# psoc6a2m register map
Vendor: Cypress Semiconductor; Series: psoc6a2m; File version: 1.0
CPU: CM4 r0p1, little endian, MPU, FPU, VTOR, 3 interrupt priority bits
Registers are 32-bit, read-write, reset 0x0 unless marked. A register's access mark holds for its fields unless they carry their own. Offsets are from the block's base; [hi:lo] are bit positions; lines under a group give offsets from that group.

## SDHC0 (part 4 of 4) — SD/eMMC Host Controller
Base 0x40460000
Same registers: SDHC1 0x40470000
0x1000 CORE group — MMIO for Synopsys Mobile Storage Host Controller IP
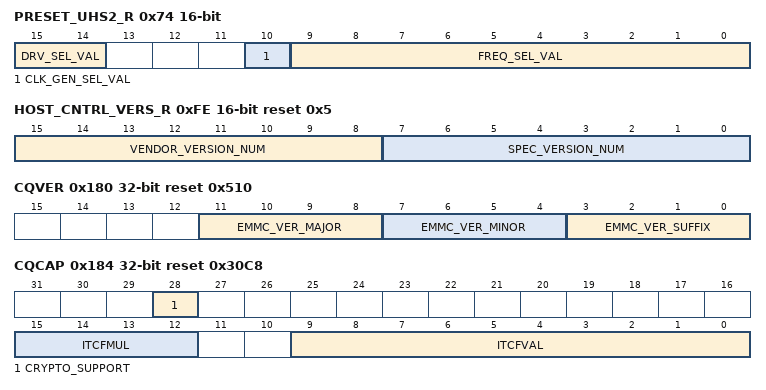
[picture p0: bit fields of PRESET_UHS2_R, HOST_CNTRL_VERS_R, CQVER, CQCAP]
  0x74 PRESET_UHS2_R 16-bit ro — Preset Value for UHS-II
    [15:14] DRV_SEL_VAL — Driver Strength Select Value These bits indicate the Driver strength value supported by 1.8V signaling bus speed modes in the SD mode. This field is meaningless for UHS-II mode. In eMMC mode, these bits can be used for selecting the Drive strength value for HS400 mode. Values: - 0x0 (TYPEB): Driver Type B is selected - 0x1 (TYPEA): Driver Type A is selected - 0x2 (TYPEC): Driver Type C is selected - 0x3 (TYPED): Driver Type D is selected
    [10] CLK_GEN_SEL_VAL — Clock Generator Select Value This bit is effective when the Host Controller supports a programmable clock generator. Values: - 0x0 (FALSE): Host Controller Ver2.0 Compatible Clock Generator - 0x1 (PROG): Programmable Clock Generator
    [9:0] FREQ_SEL_VAL — SDCLK/RCLK Frequency Select Value These bits specify the 10-bit preset value that must be set in the SDCLK/RCLK Frequency Select field of the Clock Control register, as described by a Host System.
  0x78 ADMA_ID_LOW_R — ADMA3 Integrated Descriptor Address Register - Low
    [31:0] ADMA_ID_LOW — ADMA Integrated Descriptor Address These bits indicate the lower 32-bit of the ADMA Integrated Descriptor address. The start address of Integrated Descriptor is set to these register bits. The ADMA3 fetches one Descriptor Address and increments these bits to indicate the next Descriptor address.
  0xE6 P_EMBEDDED_CNTRL 16-bit ro reset 0xF6C — Pointer for Embedded Control
    [11:0] REG_OFFSET_ADDR — Offset Address of Embedded Control register.
  0xE8 P_VENDOR_SPECIFIC_AREA 16-bit ro reset 0x500 — Pointer for Vendor Specific Area 1
    [11:0] REG_OFFSET_ADDR — Base offset Address for Vendor-Specific registers.
  0xEA P_VENDOR2_SPECIFIC_AREA 16-bit ro reset 0x180 — Pointer for Vendor Specific Area 2
    [15:0] V2SA_REG_OFFSET_ADDR — Base offset Address for Command Queuing registers.
  0xFC SLOT_INTR_STATUS_R 16-bit ro — Slot Interrupt Status Register
    [7:0] INTR_SLOT — Interrupt signal for each Slot These status bits indicate the logical OR of Interrupt signal and Wakeup signal for each slot. A maximum of 8 slots can be defined. If one interrupt signal is associated with multiple slots, the Host Driver can identify the interrupt that is generated by reading these bits. By a power on reset or by setting Software Reset For All bit, the interrupt signals are de-asserted and this status reads 00h. - Bit 00: Slot 1 - Bit 01: Slot 2 - Bit 02: Slot 3 - .......... - .......... - Bit 07: Slot 8 Note: MSHC Host Controller support single card slot. This register shall always return 0.
  0xFE HOST_CNTRL_VERS_R 16-bit ro reset 0x5 — Host Controller Version
    [15:8] VENDOR_VERSION_NUM, [7:0] SPEC_VERSION_NUM
  0x180 CQVER ro reset 0x510 — Command Queuing Version register
    [11:8] EMMC_VER_MAJOR — This bit indicates the eMMC major version (1st digit left of decimal point) in BCD format.
    [7:4] EMMC_VER_MINOR — This bit indicates the eMMC minor version (1st digit right of decimal point) in BCD format.
    [3:0] EMMC_VER_SUFFIX — This bit indicates the eMMC version suffix (2nd digit right of decimal point) in BCD format.
  0x184 CQCAP ro reset 0x30C8 — Command Queuing Capabilities register
    [28] CRYPTO_SUPPORT — Crypto Support This bit indicates whether the Host Controller supports cryptographic operations. Values: - 0x0 (FALSE): Crypto not Supported - 0x1 (TRUE): Crypto Supported
    [15:12] ITCFMUL
    [9:0] ITCFVAL — Internal Timer Clock Frequency Value (ITCFVAL) This field scales the frequency of the timer clock provided by ITCFMUL. The Final clock frequency of actual timer clock is calculated as ITCFVAL* ITCFMUL.
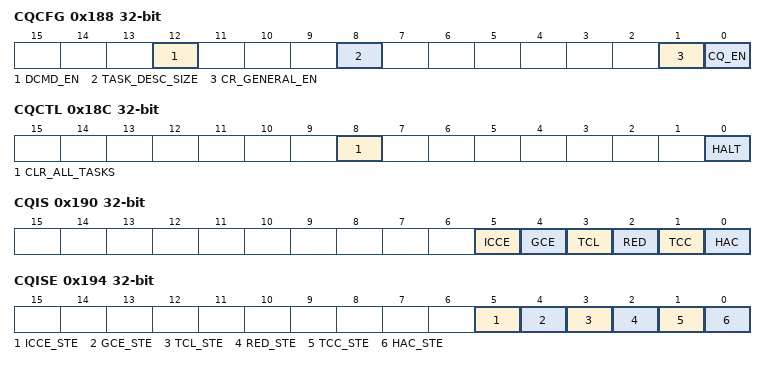
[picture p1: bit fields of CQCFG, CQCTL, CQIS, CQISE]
  0x188 CQCFG — Command Queuing Configuration register
    [12] DCMD_EN — This bit indicates to the hardware whether the Task Descriptor in slot #31 of the TDL is a data transfer descriptor or a direct-command descriptor. CQE uses this bit when a task is issued in slot #31, to determine how to decode the Task Descriptor. Values: - 0x1 (SLOT31_DCMD_ENABLE): Task descriptor in slot #31 is a DCMD Task Descriptor - 0x0 (SLOT31_DCMD_DISABLE): Task descriptor in slot #31 is a data Transfer Task Descriptor
    [8] TASK_DESC_SIZE — Bit Value Description This bit indicates the size of task descriptor used in host memory. This bit can only be configured when Command Queuing Enable bit is 0 (command queuing is disabled). Values: - 0x1 (TASK_DESC_128b): Task descriptor size is 128 bits - 0x0 (TASK_DESC_64b): Task descriptor size is 64 bits
    [1] CR_GENERAL_EN
    [0] CQ_EN — Enable command queuing engine (CQE). When CQE is disable, the software controls the eMMC bus using the registers between the addresses 0x000 to 0x1FF. Before the software writes to this bit, the software verifies that the eMMC host controller is in idle state and there are no ongoing commands or data transfers. When software wants to exit command queuing mode, it clears all previous tasks (if any) before setting this bit to 0. Values: - 0x1 (CQE_ENABLE): Enable command queuing - 0x0 (CQE_DISABLE): Disable command queuing
  0x18C CQCTL — Command Queuing Control register
    [8] CLR_ALL_TASKS — Clear all tasks This bit can only be written when the controller is halted. This bit does not clear tasks in the device. The software has to use the CMDQ_TASK_MGMT command to clear device's queue. Values: - 0x1 (CLEAR_ALL_TASKS): Clears all the tasks in the controller - 0x0 (NO_EFFECT): Programming 0 has no effect
    [0] HALT — Halt request and resume Values: - 0x1 (HALT_CQE): Software writes 1 to this bit when it wants to acquire software control over the eMMC bus and to disable CQE from issuing command on the bus. For example, issuing a Discard Task command (CMDQ_TASK_MGMT). When the software writes 1, CQE completes the ongoing task (if any in progress). After the task is completed and the CQE is in idle state, CQE does not issue new commands and indicates to the software by setting this bit to 1. The software can poll on this bit until it is set to 1 and only then send commands on the eMMC bus. - 0x0 (RESUME_CQE): Software writes 0 to this bit to exit from the halt state and resume CQE activity.
  0x190 CQIS — Command Queuing Interrupt Status register
    [5] ICCE
    [4] GCE
    [3] TCL — Task cleared interrupt This status bit is asserted (if CQISE.TCL_STE=1) when a task clear operation is completed by CQE. The completed task clear operation is either an individual task clear (by writing CQTCLR) or clearing of all tasks (by writing CQCTL). A value of 1 clears this status bit. Values: - 0x1 (SET): TCL Interrupt is set - 0x0 (NOTSET): TCL Interrupt is not set
    [2] RED — Response error detected interrupt This status bit is asserted (if CQISE.RED_STE=1) when a response is received with an error bit set in the device status field. Configure the CQRMEM register to identify device status bit fields that may trigger an interrupt and that are masked. A value of 1 clears this status bit. Values: - 0x1 (SET): RED Interrupt is set - 0x0 (NOTSET): RED Interrupt is not set
    [1] TCC — Task complete interrupt This status bit is asserted (if CQISE.TCC_STE=1) when at least one of the following conditions are met: - A task is completed and the INT bit is set in its Task Descriptor - Interrupt caused by Interrupt Coalescing logic due to timeout - Interrupt Coalescing logic reached the configured threshold A value of 1 clears this status bit Values: - 0x1 (SET): TCC Interrupt is set - 0x0 (NOTSET): TCC Interrupt is not set
    [0] HAC — Halt complete interrupt This status bit is asserted (only if CQISE.HAC_STE=1) when halt bit in the CQCTL register transitions from 0 to 1 indicating that the host controller has completed its current ongoing task and has entered halt state. A value of 1 clears this status bit. Values: - 0x1 (SET): HAC Interrupt is set - 0x0 (NOTSET): HAC Interrupt is not set
  0x194 CQISE — Command Queuing Interrupt Status Enable register
    [5] ICCE_STE — Invalid Crypto Configuration Error interrupt status enable Values: - 0x1 (INT_STS_ENABLE): CQIS.ICCE is set when its interrupt condition is active - 0x0 (INT_STS_DISABLE): CQIS.ICCE is disabled
    [4] GCE_STE — General Crypto Error interrupt status enable Values: - 0x1 (INT_STS_ENABLE): CQIS.GCE is set when its interrupt condition is active - 0x0 (INT_STS_DISABLE): CQIS.GCE is disabled
    [3] TCL_STE — Task cleared interrupt status enable Values: - 0x1 (INT_STS_ENABLE): CQIS.TCL is set when its interrupt condition is active - 0x0 (INT_STS_DISABLE): CQIS.TCL is disabled
    [2] RED_STE — Response error detected interrupt status enable Values: - 0x1 (INT_STS_ENABLE): CQIS.RED is set when its interrupt condition is active - 0x0 (INT_STS_DISABLE): CQIS.RED is disabled
    [1] TCC_STE — Task complete interrupt status enable Values: - 0x1 (INT_STS_ENABLE): CQIS.TCC is set when its interrupt condition is active - 0x0 (INT_STS_DISABLE): CQIS.TCC is disabled
    [0] HAC_STE — Halt complete interrupt status enable Values: - 0x1 (INT_STS_ENABLE): CQIS.HAC is set when its interrupt condition is active - 0x0 (INT_STS_DISABLE): CQIS.HAC is disabled
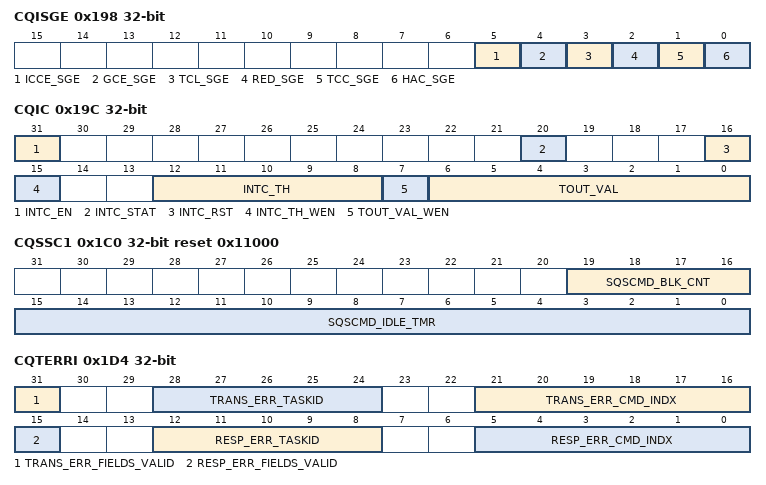
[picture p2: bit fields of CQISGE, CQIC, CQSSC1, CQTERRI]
  0x198 CQISGE — Command Queuing Interrupt signal enable register
    [5] ICCE_SGE — Invalid Crypto Configuration Error interrupt signal enable Values: - 0x1 (INT_SIG_ENABLE): CQIS.ICCE interrupt signal generation is active - 0x0 (INT_SIG_DISABLE): CQIS.ICCE interrupt signal generation is disabled
    [4] GCE_SGE — General Crypto Error interrupt signal enable Values: - 0x1 (INT_SIG_ENABLE): CQIS.GCE interrupt signal generation is active - 0x0 (INT_SIG_DISABLE): CQIS.GCE interrupt signal generation is disabled
    [3] TCL_SGE — Task cleared interrupt signal enable Values: - 0x1 (INT_SIG_ENABLE): CQIS.TCL interrupt signal generation is active - 0x0 (INT_SIG_DISABLE): CQIS.TCL interrupt signal generation is disabled
    [2] RED_SGE — Response error detected interrupt signal enable Values: - 0x1 (INT_SIG_ENABLE): CQIS.RED interrupt signal generation is active - 0x0 (INT_SIG_DISABLE): CQIS.RED interrupt signal generation is disabled
    [1] TCC_SGE — Task complete interrupt signal enable Values: - 0x1 (INT_SIG_ENABLE): CQIS.TCC interrupt signal generation is active - 0x0 (INT_SIG_DISABLE): CQIS.TCC interrupt signal generation is disabled
    [0] HAC_SGE — Halt complete interrupt signal enable Values: - 0x1 (INT_SIG_ENABLE): CQIS.HAC interrupt signal generation is active - 0x0 (INT_SIG_DISABLE): CQIS.HAC interrupt signal generation is disabled
  0x19C CQIC — Command Queuing Interrupt Coalescing register
    [31] INTC_EN — Interrupt Coalescing Enable Bit Values: - 0x1 (ENABLE_INT_COALESCING): Interrupt coalescing mechanism is active. Interrupts are counted and timed, and coalesced interrupts are generated - 0x0 (DISABLE_INT_COALESCING): Interrupt coalescing mechanism is disabled (Default).
    [20] INTC_STAT ro — Interrupt Coalescing Status Bit This bit indicates to the software whether any tasks (with INT=0) have completed and counted towards interrupt coalescing (that is, this is set if and only if INTC counter > 0). Values: - 0x1 (INTC_ATLEAST1_COMP): At least one INT0 task completion has been counted (INTC counter > 0) - 0x0 (INTC_NO_TASK_COMP): INT0 Task completions have not occurred since last counter reset (INTC counter == 0)
    [16] INTC_RST wo — Counter and Timer Reset When host driver writes 1, the interrupt coalescing timer and counter are reset. Values: - 0x1 (ASSERT_INTC_RESET): Interrupt coalescing timer and counter are reset - 0x0 (NO_EFFECT): No Effect
    [15] INTC_TH_WEN wo — Interrupt Coalescing Counter Threshold Write Enable When software writes 1 to this bit, the value INTC_TH is updated with the contents written on the same cycle. Values: - 0x1 (WEN_SET): Sets INTC_TH_WEN - 0x0 (WEN_CLR): Clears INTC_TH_WEN
    [12:8] INTC_TH wo — Interrupt Coalescing Counter Threshold filed Software uses this field to configure the number of task completions (only tasks with INT=0 in the Task Descriptor), which are required in order to generate an interrupt. Counter Operation: As data transfer tasks with INT=0 complete, they are counted by CQE. The counter is reset by software during the interrupt service routine. The counter stops counting when it reaches the value configured in INTC_TH, and generates interrupt. - 0x0: Interrupt coalescing feature disabled - 0x1: Interrupt coalescing interrupt generated after 1 task when INT=0 completes - 0x2: Interrupt coalescing interrupt generated after 2 tasks when INT=0 completes - ........ - 0x1f: Interrupt coalescing interrupt generated after 31 tasks when INT=0 completes To write to this field, the INTC_TH_WEN bit must be set during the same write operation.
    [7] TOUT_VAL_WEN wo — When software writes 1 to this bit, the value TOUT_VAL is updated with the contents written on the same cycle. Values: - 0x1 (WEN_SET): Sets TOUT_VAL_WEN - 0x0 (WEN_CLR): clears TOUT_VAL_WEN
    [6:0] TOUT_VAL — Interrupt Coalescing Timeout Value Software uses this field to configure the maximum time allowed between the completion of a task on the bus and the generation of an interrupt. Timer Operation: The timer is reset by software during the interrupt service routine. It starts running when the first data transfer task with INT=0 is completed, after the timer was reset. When the timer reaches the value configured in ICTOVAL field, it generates an interrupt and stops. The timer's unit is equal to 1024 clock periods of the clock whose frequency is specified in the Internal Timer Clock Frequency field CQCAP register. - 0x0: Timer is disabled. Timeout-based interrupt is not generated - 0x1: Timeout on 01x1024 cycles of timer clock frequency - 0x2: Timeout on 02x1024 cycles of timer clock frequency - ........ - 0x7f: Timeout on 127x1024 cycles of timer clock frequency In order to write to this field, the TOUT_VAL_WEN bit must be set at the same write operation.
  0x1A0 CQTDLBA — Command Queuing Task Descriptor List Base Address register
    [31:0] TDLBA — This register stores the LSB bits (31:0) of the byte address of the head of the Task Descriptor List in system memory. The size of the task descriptor list is 32 * (Task Descriptor size + Transfer Descriptor size) as configured by the host driver. This address is set on 1 KB boundary. The lower 10 bits of this register are set to 0 by the software and are ignored by CQE.
  0x1A8 CQTDBR — Command Queuing DoorBell register
    [31:0] DBR — The software configures TDLBA and TDLBAU, and enable CQE in CQCFG before using this register. Writing 1 to bit n of this register triggers CQE to start processing the task encoded in slot n of the TDL. Writing 0 by the software does not have any impact on the hardware, and does not change the value of the register bit. CQE always processes tasks according to the order submitted to the list by CQTDBR write transactions. CQE processes Data Transfer tasks by reading the Task Descriptor and sending QUEUED_TASK_PARAMS (CMD44) and QUEUED_TASK_ADDRESS (CMD45) commands to the device. CQE processes DCMD tasks (in slot #31, when enabled) by reading the Task Descriptor, and generating the command encoded by its index and argument. The corresponding bit is cleared to 0 by CQE in one of the following events: - A task execution is completed (with success or error). - The task is cleared using CQTCLR register. - All tasks are cleared using CQCTL register. - CQE is disabled using CQCFG register. Software may initiate multiple tasks at the same time (batch submission) by writing 1 to multiple bits of this register in the same transaction. In the case of batch submission, CQE processes the tasks in order of the task index, starting with the lowest index. If one or more tasks in the batch are marked with QBR, the ordering of execution is based on said processing order.
  0x1AC CQTCN — Command Queuing TaskClear Notification register
    [31:0] TCN — Task Completion Notification Each of the 32 bits are bit mapped to the 32 tasks. - Bit-N(1): Task-N has completed execution (with success or errors) - Bit-N(0): Task-N has not completed, could be pending or not submitted. On task completion, software may read this register to know tasks that have completed. After reading this register, software may clear the relevant bit fields by writing 1 to the corresponding bits.
  0x1B0 CQDQS ro — Device queue status register
    [31:0] DQS — Device Queue Status Each of the 32 bits are bit mapped to the 32 tasks. - Bit-N(1): Device has marked task N as ready for execution - Bit-N(0): Task-N is not ready for execution. This task could be pending in device or not submitted. Host controller updates this register with response of the Device Queue Status command.
  0x1B4 CQDPT ro — Device pending tasks register
    [31:0] DPT — Device-Pending Tasks Each of the 32 bits are bit mapped to the 32 tasks. - Bit-N(1): Task-N has been successfully queued into the device and is awaiting execution - Bit-N(0): Task-N is not yet queued. Bit n of this register is set if and only if QUEUED_TASK_PARAMS (CMD44) and QUEUED_TASK_ADDRESS (CMD45) were sent for this specific task and if this task has not been executed. The controller sets this bit after receiving a successful response for CMD45. CQE clears this bit after the task has completed execution. Software reads this register in the task-discard procedure to determine if the task is queued in the device.
  0x1B8 CQTCLR — Command Queuing DoorBell register
    [31:0] TCLR — Writing 1 to bit n of this register orders CQE to clear a task that the software has previously issued. This bit can only be written when CQE is in Halt state as indicated in CQCFG register Halt bit. When software writes 1 to a bit in this register, CQE updates the value to 1, and starts clearing the data structures related to the task. CQE clears the bit fields (sets a value of 0) in CQTCLR and in CQTDBR once the clear operation is complete. Software must poll on the CQTCLR until it is cleared to verify that a clear operation was done.
  0x1C0 CQSSC1 reset 0x11000 — CQ Send Status Configuration 1 register
    [19:16] SQSCMD_BLK_CNT — This field indicates when SQS CMD is sent while data transfer is in progress. A value of 'n' indicates that CQE sends status command on the CMD line, during the transfer of data block BLOCK_CNTn, on the data lines, where BLOCK_CNT is the number of blocks in the current transaction. - 0x0: SEND_QUEUE_STATUS (CMD13) command is not sent during the transaction. Instead, it is sent only when the data lines are idle. - 0x1: SEND_QUEUE_STATUS command is to be sent during the last block of the transaction. - 0x2: SEND_QUEUE_STATUS command when last 2 blocks are pending. - 0x3: SEND_QUEUE_STATUS command when last 3 blocks are pending. - ........ - 0xf: SEND_QUEUE_STATUS command when last 15 blocks are pending. Should be programmed only when CQCFG.CQ_EN is '0'
    [15:0] SQSCMD_IDLE_TMR — This field configures the polling period to be used when using periodic SEND_QUEUE_STATUS (CMD13) polling. Periodic polling is used when tasks are pending in the device, but no data transfer is in progress. When a SEND_QUEUE_STATUS response indicates that no task is ready for execution, CQE counts the configured time until it issues the next SEND_QUEUE_STATUS. Timer units are clock periods of the clock whose frequency is specified in the Internal Timer Clock Frequency field CQCAP register. The minimum value is 0001h (1 clock period) and the maximum value is FFFFh (65535 clock periods). For example, a CQCAP field value of 0 indicates a 19.2 MHz clock frequency (period = 52.08 ns). If the setting in CQSSC1.CIT is 1000h, the calculated polling period is 4096*52.08 ns= 213.33 ns. Should be programmed only when CQCFG.CQ_EN is '0'.
  0x1C4 CQSSC2 — CQ Send Status Configuration 2 register
    [15:0] SQSCMD_RCA — This field provides CQE with the contents of the 16-bit RCA field in SEND_QUEUE_STATUS (CMD13) command argument. CQE copies this field to bits 31:16 of the argument when transmitting SEND_ QUEUE_STATUS (CMD13) command.
  0x1C8 CQCRDCT ro — Command response for direct command register
    [31:0] DCMD_RESP — This register contains the response of the command generated by the last direct command (DCMD) task that was sent. Contents of this register are valid only after bit 31 of CQTDBR register is cleared by the controller.
  0x1D0 CQRMEM reset 0xFDF9A080 — Command response mode error mask register
    [31:0] RESP_ERR_MASK — The bits of this field are bit mapped to the device response. This bit is used as an interrupt mask on the device status filed that is received in R1/R1b responses. - 1: When a R1/R1b response is received, with a bit i in the device status set, a RED interrupt is generated. - 0: When a R1/R1b response is received, bit i in the device status is ignored. The reset value of this register is set to trigger an interrupt on all 'Error' type bits in the device status. Note: Responses to CMD13 (SQS) encode the QSR so that they are ignored by this logic.
  0x1D4 CQTERRI ro — CQ Task Error Information register
    [31] TRANS_ERR_FIELDS_VALID — This bit is updated when an error is detected while a data transfer transaction was in progress. Values: - 0x1 (SET): data transfer related error detected. Check contents of TRANS_ERR_TASKID and TRANS_ERR_CMD_INDX fields - 0x0 (NOT_SET): Ignore contents of TRANS_ERR_TASKID and TRANS_ERR_CMD_INDX
    [28:24] TRANS_ERR_TASKID — This field captures the ID of the task that was executed and whose data transfer has errors.
    [21:16] TRANS_ERR_CMD_INDX — This field captures the index of the command that was executed and whose data transfer has errors.
    [15] RESP_ERR_FIELDS_VALID — This bit is updated when an error is detected while a command transaction was in progress. Values: - 0x1 (SET): Response-related error is detected. Check contents of RESP_ERR_TASKID and RESP_ERR_CMD_INDX fields - 0x0 (NOT_SET): Ignore contents of RESP_ERR_TASKID and RESP_ERR_CMD_INDX
    [12:8] RESP_ERR_TASKID — This field captures the ID of the task which was executed on the command line when the error occurred.
    [5:0] RESP_ERR_CMD_INDX — This field captures the index of the command that was executed on the command line when the error occurred.
  0x1D8 CQCRI ro — CQ Command response index
    [5:0] CMD_RESP_INDX — Last Command Response index This field stores the index of the last received command response. Controller updates the value every time a command response is received.
  0x1DC CQCRA ro — CQ Command response argument register
    [31:0] CMD_RESP_ARG — Last Command Response argument This field stores the argument of the last received command response. Controller updates the value every time a command response is received.
  0x500 MSHC_VER_ID_R ro reset 0x3137302A — MSHC version
    [31:0] MSHC_VER_ID — Current release number This field indicates the Synopsys DesignWare Cores DWC_mshc/DWC_mshc_lite current release number that is read by an application. For example, release number '1.60a' is represented in ASCII as 0x313630. Lower 8 bits read from this register can be ignored by the application. An application reading this register in conjunction with the MSHC_VER_TYPE_R register, gathers details of the current release.
  0x504 MSHC_VER_TYPE_R ro reset 0x67612A2A — MSHC version type
    [31:0] MSHC_VER_TYPE — Current release type This field indicates the Synopsys DesignWare Cores DWC_mshc/DWC_mshc_lite current release type that is read by an application. For example, release type is 'ga' is represented in ASCII as 0x6761. Lower 16 bits read from this register can be ignored by the application. An application reading this register in conjunction with the MSHC_VER_ID_R register, gathers details of the current release.
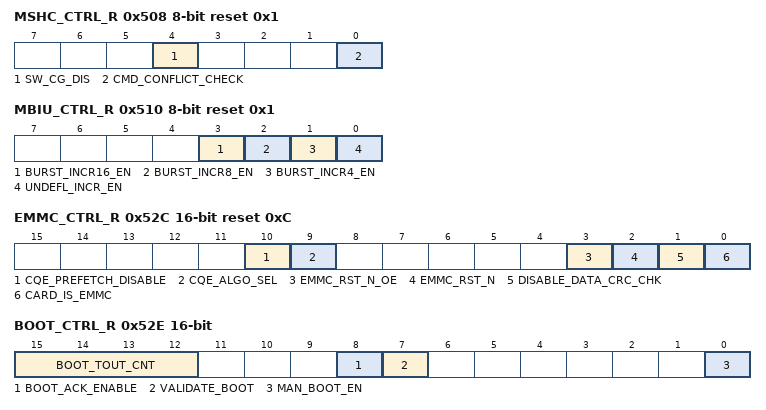
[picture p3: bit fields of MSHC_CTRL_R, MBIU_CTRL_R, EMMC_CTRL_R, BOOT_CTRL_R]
  0x508 MSHC_CTRL_R 8-bit reset 0x1 — MSHC Control register
    [4] SW_CG_DIS — Internal clock gating disable control This bit must be used to disable IP's internal clock gating when required. when disabled clocks are not gated. Clocks to the core (except hclk) must be stopped when programming this bit. Values: - 0x0 (ENABLE): Internal clock gates are active and clock gating is controlled internally - 0x1 (DISABLE): Internal clock gating is disabled, clocks are not gated internally
    [0] CMD_CONFLICT_CHECK — Command conflict check This bit enables command conflict check. Note: DWC_mshc controller monitors the CMD line whenever a command is issued and checks whether the value driven on sd_cmd_out matches the value on sd_cmd_in at next subsequent edge of cclk_tx to determine command conflict error. This bit is cleared only if the feed back delay (including IO Pad delay) is more than (t_card_clk_period - t_setup), where t_setup is the setup time of a flop in DWC_mshc. The I/O pad delay is consistent across CMD and DATA lines, and it is within the value: (2*t_card_clk_period - t_setup) Values: - 0x0 (DISABLE_CMD_CONFLICT_CHK): Disable command conflict check - 0x1 (CMD_CONFLICT_CHK_LAT1): Check for command conflict after 1 card clock cycle
  0x510 MBIU_CTRL_R 8-bit reset 0x1 — MBIU Control register
    [3] BURST_INCR16_EN — INCR16 Burst Controls generation of INCR16 transfers on Master interface. Values: - 0x0 (FALSE): AHB INCR16 burst type is not generated on Master I/F - 0x1 (TRUE): AHB INCR16 burst type can be generated on Master I/F
    [2] BURST_INCR8_EN — INCR8 Burst Controls generation of INCR8 transfers on Master interface. Values: - 0x0 (FALSE): AHB INCR8 burst type is not generated on Master I/F - 0x1 (TRUE): AHB INCR8 burst type can be generated on Master I/F
    [1] BURST_INCR4_EN — INCR4 Burst Controls generation of INCR4 transfers on Master interface. Values: - 0x0 (FALSE): AHB INCR4 burst type is not generated on Master I/F - 0x1 (TRUE): AHB INCR4 burst type can be generated on Master I/F
    [0] UNDEFL_INCR_EN — Undefined INCR Burst Controls generation of undefined length INCR transfer on Master interface. Values: - 0x0 (FALSE): Undefined INCR type burst is the least preferred burst on AHB Master I/F - 0x1 (TRUE): Undefined INCR type burst is the most preferred burst on AHB Master I/F
  0x52C EMMC_CTRL_R 16-bit reset 0xC — eMMC Control register
    [10] CQE_PREFETCH_DISABLE — Enable or Disable CQE's PREFETCH feature This field allows Software to disable CQE's data prefetch feature when set to 1. Values: - 0x0 (PREFETCH_ENABLE): CQE can Prefetch data for sucessive WRITE transfers and pipeline sucessive READ transfers - 0x1 (PREFETCH_DISABLE): Prefetch for WRITE and Pipeline for READ are disabled
    [9] CQE_ALGO_SEL — Scheduler algorithm selected for execution This bit selects the Algorithm used for selecting one of the many ready tasks for execution. Values: - 0x0 (PRI_REORDER_PLUS_FCFS): Priority based reordering with FCFS to resolve equal priority tasks - 0x1 (FCFS_ONLY): First come First serve, in the order of DBR rings
    [3] EMMC_RST_N_OE — Output Enable control for EMMC Device Reset signal PAD control. This field drived sd_rst_n_oe output of DWC_mshc Values: - 0x1 (ENABLE): sd_rst_n_oe is 1 - 0x0 (DISABLE): sd_rst_n_oe is 0
    [2] EMMC_RST_N — EMMC Device Reset signal control. This register field controls the sd_rst_n output of DWC_mshc Values: - 0x1 (RST_DEASSERT): Reset to eMMC device is deasserted - 0x0 (RST_ASSERT): Reset to eMMC device asserted (active low)
    [1] DISABLE_DATA_CRC_CHK — Disable Data CRC Check This bit controls masking of CRC16 error for Card Write in eMMC mode. This is useful in bus testing (CMD19) for an eMMC device. In bus testing, an eMMC card does not send CRC status for a block, which may generate CRC error. This CRC error can be masked using this bit during bus testing. Values: - 0x1 (DISABLE): DATA CRC check is disabled - 0x0 (ENABLE): DATA CRC check is enabled
    [0] CARD_IS_EMMC — eMMC Card present This bit indicates the type of card connected. An application program this bit based on the card connected to MSHC. Values: - 0x1 (EMMC_CARD): Card connected to MSHC is an eMMC card - 0x0 (NON_EMMC_CARD): Card connected to MSHC is a non-eMMC card
  0x52E BOOT_CTRL_R 16-bit — eMMC Boot Control register
    [15:12] BOOT_TOUT_CNT
    [8] BOOT_ACK_ENABLE — Boot Acknowledge Enable When this bit set, DWC_mshc checks for boot acknowledge start pattern of 0-1-0 during boot operation. This bit is applicable for both mandatory and alternate boot mode. Values: - 0x1 (TRUE): Boot Ack enable - 0x0 (FALSE): Boot Ack disable
    [7] VALIDATE_BOOT wo — Validate Mandatory Boot Enable bit This bit is used to validate the MAN_BOOT_EN bit. Values: - 0x1 (TRUE): Validate Mandatory boot enable bit - 0x0 (FALSE): Ignore Mandatory boot Enable bit
    [0] MAN_BOOT_EN — Mandatory Boot Enable This bit is used to initiate the mandatory boot operation. The application sets this bit along with VALIDATE_BOOT bit. Writing 0 is ignored. The DWC_mshc clears this bit after the boot transfer is completed or terminated. Values: - 0x1 (MAN_BOOT_EN): Mandatory boot enable - 0x0 (MAN_BOOT_DIS): Mandatory boot disable
  0x530 GP_IN_R ro — General Purpose Input register
    [0] GP_IN — It reflects the value of gp_in ports. NOT USED - ALWAYS READS 0
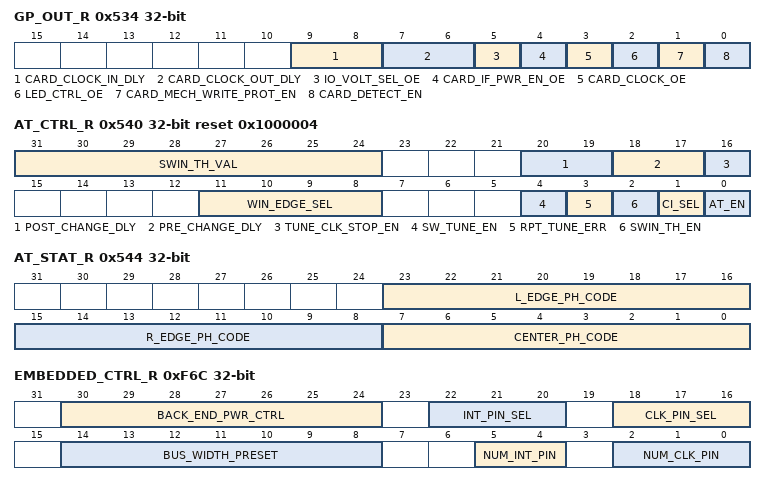
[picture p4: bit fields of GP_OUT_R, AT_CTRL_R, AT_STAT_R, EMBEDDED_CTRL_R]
  0x534 GP_OUT_R — General Purpose Output register
    [9:8] CARD_CLOCK_IN_DLY — Delay CARD_CLOCK input internally to optimally sample CMD/DAT; interface protocol mode associaton to the 4 selections are TBD.
    [7:6] CARD_CLOCK_OUT_DLY — Delay CARD_CLOCK output relative to CMD/DAT according to the following: 00: ~7 ns (Default - can be used for SD: DS, HS, SDR12 and SDR25; eMMC BWC and SDR) 01: ~5 ns (can be used for SD SDR50 and DDR50) 10: ~3 ns (can be used for eMMC DDR) 11: ~1 ns (may be useful in DDR modes in certain circumstances)
    [5] IO_VOLT_SEL_OE — Active high output enable for the IO voltage selection signal io_volt_sel controlled through HOST_CTRL_2.SIGNALING_EN: 0: disable OE to the io_volt_sel output 1: enable OE to the io_volt_sel output
    [4] CARD_IF_PWR_EN_OE — Active high output enable for the card interface power enable output card_if_pwr_en controlled through PWR_CTRL_R.SD_BUS_PWR_VDD1: 0: disable OE to the card_if_pwr_en output 1: enable OE to the card_if_pwr_en output
    [3] CARD_CLOCK_OE — Active high output enable for the card clock output clk_card which is gated by CLK_CTRL_R.SD_CLK_EN: 0: disable OE to the clk_card output 1: enable OE to the clk_card output
    [2] LED_CTRL_OE — Active high output enable for the LED output signal led_ctrl controlled through HOST_CTRL1_R.LED_CTRL: 0: disable OE associated with the led_ctrl output 1: enable OE associated with the led_ctrl output
    [1] CARD_MECH_WRITE_PROT_EN — 0: Force card_mech_write_prot input to 0 1: Normal card_mech_write_prot operation allowing mechanical write protection from a device pin
    [0] CARD_DETECT_EN — 0: Force card_detect_n input to 0 1: Normal card_detect_n operation allowing card detection from a device pin
  0x540 AT_CTRL_R reset 0x1000004 — Tuning and Auto-tuning control register
    [31:24] SWIN_TH_VAL — Sampling window threshold value setting The maximum value that can be set here depends on the length of delayline used for tuning. A delayLine with 128 taps can use values from 0x0 to 0x7F. This field is valid only when SWIN_TH_EN is '1'. Should be programmed only when SAMPLE_CLK_SEL is '0' - 0x0 - Threshold values is 0x1, windows of length 1 tap and above can be selected as sampling window. - 0x1 - Threshold values is 0x2, windows of length 2 taps and above can be selected as sampling window. - 0x2 - Threshold values is 0x1, windows of length 3 taps and above can be selected as sampling window. - ........ - 0x7F - Threshold values is 0x1, windows of length 127 taps and above can be selected as sampling window.
    [20:19] POST_CHANGE_DLY — Time taken for phase switching and stable clock output. Specifies the maximum time (in terms of cclk cycles) that the delay line can take to switch its output phase after a change in tuning_cclk_sel or autotuning_cclk_sel. Values: - 0x0 (LATENCY_LT_1): Less than 1-cycle latency - 0x1 (LATENCY_LT_2): Less than 2-cycle latency - 0x2 (LATENCY_LT_3): Less than 3-cycle latency - 0x3 (LATENCY_LT_4): Less than 4-cycle latency
    [18:17] PRE_CHANGE_DLY — Maximum Latency specification between cclk_tx and cclk_rx. Values: - 0x0 (LATENCY_LT_1): Less than 1-cycle latency - 0x1 (LATENCY_LT_2): Less than 2-cycle latency - 0x2 (LATENCY_LT_3): Less than 3-cycle latency - 0x3 (LATENCY_LT_4): Less than 4-cycle latency
    [16] TUNE_CLK_STOP_EN — Clock stopping control for Tuning and auto-tuning circuit. When enabled, clock gate control output (clk2card_on) is pulled low before changing phase select codes on tuning_cclk_sel and autotuning_cclk_sel. This effectively stops the Device/Card clock, cclk_rx and also drift_cclk_rx. Changing phase code when clocks are stopped ensures glitch free phase switching. Set this bit to 0 if the PHY or delayline can guarantee glitch free switching. Values: - 0x1 (ENABLE_CLK_STOPPING): Clocks stopped during phase code change - 0x0 (DISABLE_CLK_STOPPING): Clocks not stopped. PHY ensures glitch free phase switching.
    [11:8] WIN_EDGE_SEL — This field sets the phase for Left and Right edges for drift monitoring. [Left edge offset + Right edge offset] must not be less than total taps of delayLine. - 0x0: User selection disabled. Tuning calculated edges are used. - 0x1: Right edge Phase is center + 2 stages, Left edge Phase is center - 2 stages. - 0x2: Right edge Phase is center + 3 stages, Left edge Phase is center - 3 stages. - ... - 0xF: Right edge Phase is center + 16 stages, Left edge Phase is center - 16 stages.
    [4] SW_TUNE_EN — This fields enables software-managed tuning flow. Values: - 0x1 (SW_TUNING_ENABLE): Software-managed tuning enabled. AT_STAT_R.CENTER_PH_CODE Field is now writable. - 0x0 (SW_TUNING_DISABLE): Software-managed tuning disabled.
    [3] RPT_TUNE_ERR — Framing errors are not generated when executing tuning. This debug bit allows users to report these errors. Values: - 0x1 (DEBUG_ERRORS): Debug mode for reporting framing errors - 0x0 (ERRORS_DISABLED): Default mode where as per SD-HCI no errors are reported.
    [2] SWIN_TH_EN — Sampling window Threshold enable Selects the tuning mode Field should be programmed only when SAMPLE_CLK_SEL is '0' Values: - 0x1 (THRESHOLD_MODE): Tuning engine selects the first complete sampling window that meets the threshold set by SWIN_TH_VAL field - 0x0 (LARGEST_WIN_MODE): Tuning engine sweeps all taps and settles at the largest window
    [1] CI_SEL — Selects the interval when the corrected center phase select code can be driven on tuning_cclk_sel output. Values: - 0x0 (WHEN_IN_BLK_GAP): Driven in block gap interval - 0x1 (WHEN_IN_IDLE): Driven at the end of the transfer
    [0] AT_EN — Setting this bit enables Auto tuning engine. This bit is enabled by default when core is configured with mode3 retuning support. Clear this bit to 0 when core is configured to have Mode3 re-tuning but SW wishes to disable mode3 retuning. This field should be programmed only when CLK_CTRL_R.SD_CLK_EN is 0. Values: - 0x1 (AT_ENABLE): AutoTuning is enabled - 0x0 (AT_DISABLE): AutoTuning is disabled
  0x544 AT_STAT_R — Tuning and Auto-tuning status register
    [23:16] L_EDGE_PH_CODE ro — Left Edge Phase code. Reading this field returns the phase code value used by Auto-tuning engine to sample data on Left edge of sampling window.
    [15:8] R_EDGE_PH_CODE ro — Right Edge Phase code. Reading this field returns the phase code value used by Auto-tuning engine to sample data on Right edge of sampling window.
    [7:0] CENTER_PH_CODE — Centered Phase code. Reading this field returns the current value on tuning_cclk_sel output. Setting AT_CTRL_R.SW_TUNE_EN enables software to write to this field and its contents are reflected on tuning_cclk_sel.
  0xF6C EMBEDDED_CTRL_R — Embedded Control register
    [30:24] BACK_END_PWR_CTRL — Back-End Power Control (SD Mode) Each bit of this field controls back-end power supply for an embedded device. - 0 - Back-End Power is off - 1 - Back-End Power is supplied D24 - Back-End Power for Device 1 D25 - Back-End Power for Device 2 D26 - Back-End Power for Device 3 D27 - Back-End Power for Device 4 D28 - Back-End Power for Device 5 D29 - Back-End Power for Device 6 D30 - Back-End Power for Device 7
    [22:20] INT_PIN_SEL — Interrupt Pin Select These bits enable the interrupt pin inputs. - 000 - Interrupts (INT_A,INT_B,INT_C) are disabled - xx1 - INT_A is enabled - x1x - INT_B is enabled - 1xx - INT_C is enabled
    [18:16] CLK_PIN_SEL — Clock Pin Select (SD Mode) This bit is selected by one of clock pin outputs. - 0x0 - Clock pins are disabled - 0x1 - CLK[1] is selected - 0x2 - CLK[2] is selected - . . - . . - . . - 0x7 - CLK[7] is selected
    [14:8] BUS_WIDTH_PRESET ro — Bus Width Preset (SD Mode) Each bit of this field specifies the bus width for each embedded device. The shared bus supports mixing of 4-bit and 8-bit bus width devices. - D08 - Bus Width Preset for Device 1 - D09 - Bus Width Preset for Device 2 - D10 - Bus Width Preset for Device 3 - D11 - Bus Width Preset for Device 4 - D12 - Bus Width Preset for Device 5 - D13 - Bus Width Preset for Device 6 - D14 - Bus Width Preset for Device 7 Function of each bit is defined as follows: - 0 - 4-bit bus width mode - 1 - 8-bit bus width mode
    [5:4] NUM_INT_PIN ro — Number of Interrupt Input Pins This field indicates support of interrupt input pins for an embedded system.
    [2:0] NUM_CLK_PIN ro — Number of Clock Pins (SD Mode) This field indicates support of clock pins to select one of devices for shared bus system. Up to 7 clock pins can be supported. - 0x0 - Shared bus is not supported - 0x1 - 1 SDCLK is supported - 0x2 - 2 SDCLK is supported - . . - . . - . . - 0x7 - 7 SDCLK is supported
